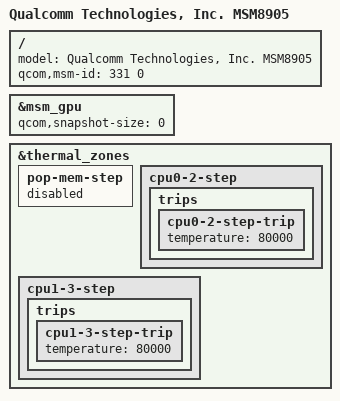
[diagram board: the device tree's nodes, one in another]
/*
 * Copyright (c) 2017-2018, 2020, The Linux Foundation. All rights reserved.
 *
 * This program is free software; you can redistribute it and/or modify
 * it under the terms of the GNU General Public License version 2 and
 * only version 2 as published by the Free Software Foundation.
 *
 * This program is distributed in the hope that it will be useful,
 * but WITHOUT ANY WARRANTY; without even the implied warranty of
 * MERCHANTABILITY or FITNESS FOR A PARTICULAR PURPOSE.  See the
 * GNU General Public License for more details.
 */

/ {
	model = "Qualcomm Technologies, Inc. MSM8905";
	qcom,msm-id = <331 0>;
};

&msm_gpu {
	/* Disable GPU snapshot dumping */
	qcom,snapshot-size = <0>;
};

&thermal_zones {
	pop-mem-step {
		status = "disabled";
	};

	cpu0-2-step {
		trips {
			cpu0-2-step-trip {
				temperature = <80000>;
			};
		};
	};

	cpu1-3-step {
		trips {
			cpu1-3-step-trip {
				temperature = <80000>;
			};
		};
	};
};
